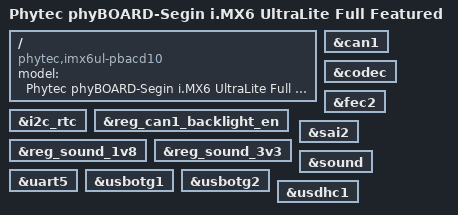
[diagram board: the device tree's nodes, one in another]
/*
 * Copyright (C) 2016 PHYTEC Messtechnik GmbH
 * Author: Christian Hemp <c.hemp@phytec.de>
 *
 * This program is free software; you can redistribute it and/or modify
 * it under the terms of the GNU General Public License version 2 as
 * published by the Free Software Foundation.
 */

/dts-v1/;
#include "imx6ul.dtsi"
#include "imx6ul-phytec-phycore-som.dtsi"
#include "imx6ul-phytec-phyboard-segin.dtsi"
#include "imx6ul-phytec-segin-peb-av-02.dtsi"

/ {

	model = "Phytec phyBOARD-Segin i.MX6 UltraLite Full Featured";
	compatible = "phytec,imx6ul-pbacd10", "phytec,imx6ul-pcl063","fsl,imx6ul";
};

&can1 {
	status = "okay";
};

&codec {
	status = "okay";
};

&fec2 {
	status = "okay";
};

&i2c_rtc {
	status = "okay";
};

&reg_can1_backlight_en {
	status = "okay";
};

&reg_sound_1v8 {
	status = "okay";
};

&reg_sound_3v3 {
	status = "okay";
};

&sai2 {
	status = "okay";
};

&sound {
	status = "okay";
};

&uart5 {
	status = "okay";
};

&usbotg1 {
	status = "okay";
};

&usbotg2 {
	status = "okay";
};

&usdhc1 {
	status = "okay";
};

